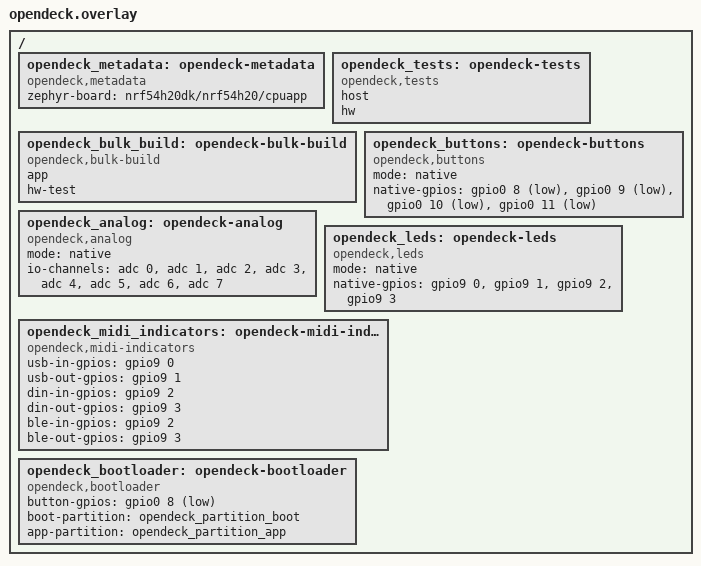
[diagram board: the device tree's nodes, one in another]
/ {
    opendeck_metadata: opendeck-metadata {
        compatible = "opendeck,metadata";
        zephyr-board = "nrf54h20dk/nrf54h20/cpuapp";
    };

    opendeck_tests: opendeck-tests {
        compatible = "opendeck,tests";
        host;
        hw;
    };

    opendeck_bulk_build: opendeck-bulk-build {
        compatible = "opendeck,bulk-build";
        app;
        hw-test;
    };

    opendeck_buttons: opendeck-buttons {
        compatible = "opendeck,buttons";
        mode = "native";
        native-gpios =
            <&gpio0 8 (GPIO_PULL_UP | GPIO_ACTIVE_LOW)>,
            <&gpio0 9 (GPIO_PULL_UP | GPIO_ACTIVE_LOW)>,
            <&gpio0 10 (GPIO_PULL_UP | GPIO_ACTIVE_LOW)>,
            <&gpio0 11 (GPIO_PULL_UP | GPIO_ACTIVE_LOW)>;
    };

    opendeck_analog: opendeck-analog {
        compatible = "opendeck,analog";
        mode = "native";
        io-channels =
            <&adc 0>,
            <&adc 1>,
            <&adc 2>,
            <&adc 3>,
            <&adc 4>,
            <&adc 5>,
            <&adc 6>,
            <&adc 7>;
    };

    opendeck_leds: opendeck-leds {
        compatible = "opendeck,leds";
        mode = "native";
        native-gpios =
            <&gpio9 0 GPIO_ACTIVE_HIGH>,
            <&gpio9 1 GPIO_ACTIVE_HIGH>,
            <&gpio9 2 GPIO_ACTIVE_HIGH>,
            <&gpio9 3 GPIO_ACTIVE_HIGH>;
    };

    opendeck_midi_indicators: opendeck-midi-indicators {
        compatible = "opendeck,midi-indicators";
        usb-in-gpios = <&gpio9 0 GPIO_ACTIVE_HIGH>;
        usb-out-gpios = <&gpio9 1 GPIO_ACTIVE_HIGH>;
        din-in-gpios = <&gpio9 2 GPIO_ACTIVE_HIGH>;
        din-out-gpios = <&gpio9 3 GPIO_ACTIVE_HIGH>;
        ble-in-gpios = <&gpio9 2 GPIO_ACTIVE_HIGH>;
        ble-out-gpios = <&gpio9 3 GPIO_ACTIVE_HIGH>;
    };

    opendeck_bootloader: opendeck-bootloader {
        compatible = "opendeck,bootloader";
        button-gpios = <&gpio0 8 (GPIO_PULL_UP | GPIO_ACTIVE_LOW)>;
        boot-partition = <&opendeck_partition_boot>;
        app-partition = <&opendeck_partition_app>;
    };
};
